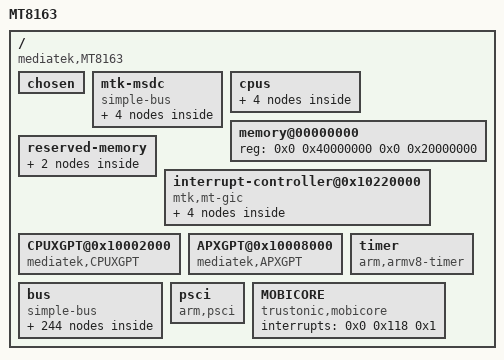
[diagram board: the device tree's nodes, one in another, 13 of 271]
/dts-v1/;

/ {
	model = "MT8163";
	compatible = "mediatek,MT8163";
	interrupt-parent = <0x1>;
	#address-cells = <0x2>;
	#size-cells = <0x2>;

	chosen {
		bootargs = "console=tty0 console=ttyMT0,921600n1 root=/dev/ram initrd=0x44000200,0x200000 loglevel=8";
	};

	mtk-msdc {
		compatible = "simple-bus";
		#address-cells = <0x1>;
		#size-cells = <0x1>;
		ranges = <0x0 0x0 0x0 0xffffffff>;

		MSDC0@0x11230000 {
			compatible = "mediatek,MSDC0";
			reg = <0x11230000 0x10000 0x10001e84 0x8 0x102061c0 0x4 0x10005000 0x1000 0x10000000 0x230>;
			interrupts = <0x0 0x4f 0x8>;
			status = "okay";
		};

		MSDC1@0x11240000 {
			compatible = "mediatek,MSDC1";
			reg = <0x11240000 0x10000 0x10001e84 0x8 0x10005000 0x1000 0x10000000 0x230>;
			interrupts = <0x0 0x50 0x8>;
			status = "okay";
		};

		MSDC2@0x11250000 {
			compatible = "mediatek,MSDC2";
			reg = <0x11250000 0x10000 0x10001e84 0x8 0x10005000 0x1000 0x10000000 0x230>;
			interrupts = <0x0 0x51 0x8>;
			status = "disabled";
		};

		MSDC3@0x11260000 {
			compatible = "mediatek,MSDC3";
			reg = <0x11260000 0x10000 0x10001e84 0x8 0x102061c0 0x4 0x10005000 0x1000 0x10000000 0x230>;
			interrupts = <0x0 0x52 0x8>;
			status = "disabled";
		};
	};

	cpus {
		#address-cells = <0x1>;
		#size-cells = <0x0>;

		cpu@0 {
			device_type = "cpu";
			compatible = "arm,cortex-a53";
			reg = <0x0>;
			enable-method = "mt-boot";
			cpu-release-addr = <0x0 0x40000200>;
			clock-frequency = "M|m";
			linux,phandle = <0x2>;
			phandle = <0x2>;
		};

		cpu@1 {
			device_type = "cpu";
			compatible = "arm,cortex-a53";
			reg = <0x1>;
			enable-method = "mt-boot";
			cpu-release-addr = <0x0 0x40000200>;
			clock-frequency = "M|m";
			linux,phandle = <0x3>;
			phandle = <0x3>;
		};

		cpu@2 {
			device_type = "cpu";
			compatible = "arm,cortex-a53";
			reg = <0x2>;
			enable-method = "mt-boot";
			cpu-release-addr = <0x0 0x40000200>;
			clock-frequency = "M|m";
			linux,phandle = <0x4>;
			phandle = <0x4>;
		};

		cpu@3 {
			device_type = "cpu";
			compatible = "arm,cortex-a53";
			reg = <0x3>;
			enable-method = "mt-boot";
			cpu-release-addr = <0x0 0x40000200>;
			clock-frequency = "M|m";
			linux,phandle = <0x5>;
			phandle = <0x5>;
		};
	};

	memory@00000000 {
		device_type = "memory";
		reg = <0x0 0x40000000 0x0 0x20000000>;
	};

	reserved-memory {
		#address-cells = <0x2>;
		#size-cells = <0x2>;
		ranges;

		consys-reserve-memory {
			compatible = "consys-reserve-memory";
			no-map;
			size = <0x0 0x200000>;
			alignment = <0x0 0x200000>;
		};

		ATF-reserved-memory {
			compatible = "ATF-reserved-memory";
			no-map;
			reg = <0x0 0x43000000 0x0 0x30000>;
		};
	};

	interrupt-controller@0x10220000 {
		compatible = "mtk,mt-gic";
		#interrupt-cells = <0x3>;
		#address-cells = <0x0>;
		interrupt-controller;
		reg = <0x0 0x10221000 0x0 0x1000 0x0 0x10222000 0x0 0x1000 0x0 0x10200620 0x0 0x1000>;
		interrupts = <0x1 0x9 0xf04>;
		linux,phandle = <0x1>;
		phandle = <0x1>;

		gic-cpuif@0 {
			compatible = "arm,gic-cpuif";
			cpuif-id = <0x0>;
			cpu = <0x2>;
		};

		gic-cpuif@1 {
			compatible = "arm,gic-cpuif";
			cpuif-id = <0x1>;
			cpu = <0x3>;
		};

		gic-cpuif@2 {
			compatible = "arm,gic-cpuif";
			cpuif-id = <0x2>;
			cpu = <0x4>;
		};

		gic-cpuif@3 {
			compatible = "arm,gic-cpuif";
			cpuif-id = <0x3>;
			cpu = <0x5>;
		};
	};

	CPUXGPT@0x10002000 {
		compatible = "mediatek,CPUXGPT";
		reg = <0x0 0x10200000 0x0 0x1000>;
		interrupts = <0x0 0x40 0x4 0x0 0x41 0x4 0x0 0x42 0x4 0x0 0x43 0x4 0x0 0x44 0x4 0x0 0x45 0x4 0x0 0x46 0x4 0x0 0x47 0x4>;
	};

	APXGPT@0x10008000 {
		compatible = "mediatek,APXGPT";
		reg = <0x0 0x10008000 0x0 0x1000>;
		interrupts = <0x0 0x98 0x8>;
		clock-frequency = <0xc65d40>;
	};

	timer {
		compatible = "arm,armv8-timer";
		interrupts = <0x1 0xd 0x8 0x1 0xe 0x8 0x1 0xb 0x8 0x1 0xa 0x8>;
		clock-frequency = <0xc65d40>;
	};

	bus {
		compatible = "simple-bus";
		#address-cells = <0x1>;
		#size-cells = <0x1>;
		ranges = <0x0 0x0 0x0 0xffffffff>;

		TOPCKGEN@0x10000000 {
			compatible = "mediatek,TOPCKGEN";
			reg = <0x10000000 0x1000>;
		};

		INFRACFG_AO@0x10001000 {
			compatible = "mediatek,INFRACFG_AO";
			reg = <0x10001000 0x1000>;
		};

		IOCFG_L@0x10002000 {
			compatible = "mediatek,IOCFG_L";
			reg = <0x10002000 0x400>;
		};

		IOCFG_B@0x10002400 {
			compatible = "mediatek,IOCFG_B";
			reg = <0x10002400 0x400>;
		};

		IOCFG_R@0x10002800 {
			compatible = "mediatek,IOCFG_R";
			reg = <0x10002800 0x400>;
		};

		IOCFG_T@0x10002C00 {
			compatible = "mediatek,IOCFG_T";
			reg = <0x10002c00 0x400>;
		};

		PERICFG@0x10003000 {
			compatible = "mediatek,PERICFG";
			reg = <0x10003000 0x1000>;
		};

		DRAMC0@0x10004000 {
			compatible = "mediatek,DRAMC0";
			reg = <0x10004000 0x1000>;
		};

		GPIO@0x10005000 {
			compatible = "mediatek,GPIO";
			reg = <0x10005000 0x1000>;
		};

		SLEEP@0x10006000 {
			compatible = "mediatek,SLEEP";
			reg = <0x10006000 0x1000>;
			interrupts = <0x0 0xa3 0x8 0x0 0xa4 0x8 0x0 0xa5 0x8 0x0 0xa6 0x8 0x0 0xa7 0x8 0x0 0xa8 0x8 0x0 0xa9 0x8 0x0 0xaa 0x8>;
		};

		TOPRGU@0x10007000 {
			compatible = "mediatek,TOPRGU";
			reg = <0x10007000 0x1000>;
			interrupts = <0x0 0x80 0x2>;
		};

		RSVD@0x10009000 {
			compatible = "mediatek,RSVD";
			reg = <0x10009000 0x1000>;
		};

		SEJ@0x1000A000 {
			compatible = "mediatek,SEJ";
			reg = <0x1000a000 0x1000>;
			interrupts = <0x0 0xac 0x8>;
		};

		EINTC@0x1000B000 {
			compatible = "mtk,mt-eic";
			reg = <0x1000b000 0x1000>;
			interrupts = <0x0 0x99 0x4>;
			#interrupt-cells = <0x2>;
			interrupt-controller;
			max_eint_num = <0xa9>;
			mapping_table_entry = <0x9b>;
			max_deint_cnt = <0x4>;
			deint_possible_irq = <0xbd 0xbe 0xbf 0xc0>;
			mapping_table = <0x0 0x16 0x1 0x17 0x2 0x18 0x3 0x19 0x4 0x1a 0x5 0x1b 0x6 0x1c 0x7 0x1d 0x8 0x1e 0x9 0x1f 0xa 0x20 0xb 0x21 0xc 0x22 0xd 0x23 0xe 0x24 0xf 0x25 0x10 0x26 0x11 0x27 0x12 0x28 0x13 0x29 0x14 0x2a 0x15 0x2b 0x16 0x0 0x17 0x1 0x18 0x2 0x19 0x3 0x1a 0x4 0x1b 0x5 0x1c 0x6 0x1d 0x7 0x1e 0x8 0x1f 0x9 0x20 0xa 0x21 0x2c 0x22 0x2d 0x23 0x2e 0x24 0x2f 0x25 0x30 0x26 0x31 0x27 0x32 0x28 0x33 0x29 0x34 0x2a 0x35 0x2b 0xb 0x2c 0xc 0x2d 0xd 0x2e 0xe 0x2f 0xf 0x30 0x10 0x31 0x11 0x32 0x12 0x33 0x13 0x34 0x14 0x35 0x36 0x36 0x37 0x37 0x38 0x38 0x39 0x39 0x3a 0x3a 0x3b 0x3b 0x3c 0x3c 0x3d 0x3d 0x3e 0x3e 0x3f 0x3f 0x40 0x40 0x41 0x41 0x42 0x42 0x43 0x43 0x44 0x44 0x45 0x45 0x46 0x46 0x47 0x47 0x48 0x48 0x49 0x49 0x4a 0x4a 0x4b 0x4b 0x4c 0x4c 0x4d 0x4d 0x4e 0x4e 0x4f 0x4f 0x50 0x50 0x51 0x51 0x52 0x52 0x53 0x53 0x54 0x54 0x55 0x55 0x56 0x56 0x57 0x57 0x58 0x58 0x59 0x59 0x5a 0x5a 0x5b 0x5b 0x5c 0x5c 0x5d 0x5d 0x5e 0x5e 0x5f 0x5f 0x60 0x60 0x61 0x61 0x62 0x62 0x63 0x63 0x64 0x64 0x65 0x65 0x66 0x66 0x67 0x67 0x68 0x68 0x69 0x69 0x6a 0x6a 0x6b 0x6b 0x6c 0x6c 0x6d 0x6d 0x6e 0x6e 0x6f 0x6f 0x70 0x70 0x71 0x71 0x72 0x72 0x73 0x73 0x74 0x74 0x75 0x75 0x76 0x76 0x77 0x77 0x78 0x78 0x79 0x79 0x7a 0x7a 0x7b 0x7b 0x7c 0x7c 0x7d 0x7d 0x7e 0x7e 0x7f 0x7f 0x80 0x80 0x81 0x81 0x82 0x82 0x83 0x83 0x84 0x84 0x85 0x85 0x86 0x86 0x87 0x87 0x88 0x88 0x89 0x89 0x8a 0x8a 0x8b 0x8b 0x8c 0x8c 0x8d 0x8d 0x8e 0x8e 0x15 0x8f 0x8f 0x90 0x90 0x91 0x91 0x92 0x92 0x93 0x93 0x94 0x94 0x95 0x95 0x96 0x96 0x97 0x97 0x98 0x98 0x99 0x99 0x9a 0x9a>;
			linux,phandle = <0x6>;
			phandle = <0x6>;

			CHR_STAT@1 {
				compatible = "mediatek, CHR_STAT-eint";
				interrupt-parent = <0x6>;
				interrupts = <0x1 0x8>;
				debounce = <0x1 0x0>;
			};

			ACCDET@4 {
				compatible = "mediatek, ACCDET-eint";
				interrupt-parent = <0x6>;
				interrupts = <0x4 0x8>;
				debounce = <0x4 0x3e800>;
			};

			MSDC1_INS@6 {
				compatible = "mediatek, MSDC1_INS-eint";
				interrupt-parent = <0x6>;
				interrupts = <0x6 0x8>;
				debounce = <0x6 0x3e8>;
			};

			ALS@8 {
				compatible = "mediatek, ALS-eint";
				interrupt-parent = <0x6>;
				interrupts = <0x8 0x8>;
				debounce = <0x8 0x0>;
			};

			GYRO@18 {
				compatible = "mediatek, GYRO-eint";
				interrupt-parent = <0x6>;
				interrupts = <0x12 0x4>;
				debounce = <0x12 0x0>;
			};

			GSE_1@19 {
				compatible = "mediatek, GSE_1-eint";
				interrupt-parent = <0x6>;
				interrupts = <0x13 0x4>;
				debounce = <0x13 0x0>;
			};

			MSE@20 {
				compatible = "mediatek, MSE-eint";
				interrupt-parent = <0x6>;
				interrupts = <0x14 0x8>;
				debounce = <0x14 0x0>;
			};

			TOUCH_PANEL@46 {
				compatible = "mediatek, TOUCH_PANEL-eint";
				interrupt-parent = <0x6>;
				interrupts = <0x2e 0x2>;
				debounce = <0x2e 0x0>;
			};
		};

		EMIMPU@0x10203000 {
			compatible = "mediatek,EMIMPU";
			reg = <0x10203000 0x1000>;
			interrupts = <0x0 0x85 0x8>;
		};

		APMIXED@0x1000C000 {
			compatible = "mediatek,APMIXED";
			reg = <0x1000c000 0x1000>;
			interrupts = <0x0 0x88 0x1>;
		};

		FHCTL@0x1000CF00 {
			compatible = "mediatek,FHCTL";
			reg = <0x1000cf00 0x100>;
		};

		PWRAP@0x1000D000 {
			compatible = "mediatek,PWRAP";
			reg = <0x1000d000 0x1000>;
			interrupts = <0x0 0xa1 0x4>;
		};

		DEVAPC_AO@0x1000E000 {
			compatible = "mediatek,DEVAPC_AO";
			reg = <0x1000e000 0x1000>;
		};

		DDRPHY@0x1000F000 {
			compatible = "mediatek,DDRPHY";
			reg = <0x1000f000 0x1000>;
		};

		KP@0x10010000 {
			compatible = "mediatek,KP";
			reg = <0x10010000 0x1000>;
			interrupts = <0x0 0xa2 0x2>;
		};

		TOPMISC@0x10011000 {
			compatible = "mediatek,TOPMISC";
			reg = <0x10011000 0x1000>;
		};

		SCP_SRAM@0x10020000 {
			compatible = "mediatek,SCP_SRAM";
			reg = <0x10020000 0x38000>;
		};

		SCP_CFGREG@0x10058000 {
			compatible = "mediatek,SCP_CFGREG";
			reg = <0x10058000 0x400>;
			interrupts = <0x0 0xae 0x4>;
		};

		SCP_MAD@0x10058400 {
			compatible = "mediatek,SCP_MAD";
			reg = <0x10058400 0x400>;
		};

		SCP_INTC@0x10058800 {
			compatible = "mediatek,SCP_INTC";
			reg = <0x10058800 0x400>;
		};

		SCP_TIMER@0x10058C00 {
			compatible = "mediatek,SCP_TIMER";
			reg = <0x10058c00 0x400>;
		};

		SCP_CLK_CTRL@0x10059000 {
			compatible = "mediatek,SCP_CLK_CTRL";
			reg = <0x10059000 0x400>;
		};

		SCP_I2C0@0x10059400 {
			compatible = "mediatek,SCP_I2C0";
			cell-index = <0x3>;
			reg = <0x10059400 0x400>;
		};

		SCP_I2C1@0x10059800 {
			compatible = "mediatek,SCP_I2C1";
			cell-index = <0x4>;
			reg = <0x10059800 0x400>;
		};

		SCP_I2C2@0x10059C00 {
			compatible = "mediatek,SCP_I2C2";
			cell-index = <0x5>;
			reg = <0x10059c00 0x400>;
		};

		SCP_GPIO@0x1005A000 {
			compatible = "mediatek,SCP_GPIO";
			reg = <0x1005a000 0x400>;
		};

		SCP_UART@0x1005A400 {
			compatible = "mediatek,SCP_UART";
			reg = <0x1005a400 0x400>;
		};

		SCP_CIRQ_EINT@0x1005A800 {
			compatible = "mediatek,SCP_CIRQ_EINT";
			reg = <0x1005a800 0x400>;
		};

		SCP_PMICWP2P@0x1005E000 {
			compatible = "mediatek,SCP_PMICWP2P";
			reg = <0x1005e000 0x1000>;
		};

		SCP_PMICWP2P@0x1005F000 {
			compatible = "mediatek,SCP_PMICWP2P";
			reg = <0x1005f000 0x1000>;
		};

		DBG_ETB@0x10100000 {
			compatible = "mediatek,DBG_ETB";
			reg = <0x10410000 0x10000 0x10430000 0x10000 0x10440000 0x10000 0x104a0000 0x10000>;
		};

		DBG_DEBUG {
			compatible = "mediatek,DBG_DEBUG";
			num = <0x8>;
			reg = <0x10810000 0x1000 0x10910000 0x1000 0x10a10000 0x1000 0x10b10000 0x1000 0x10c10000 0x1000 0x10d10000 0x1000 0x10e10000 0x1000 0x10f10000 0x1000>;
		};

		DBG_ETM {
			compatible = "mediatek,DBG_ETM";
			num = <0x8>;
			reg = <0x10840000 0x1000 0x10940000 0x1000 0x10a40000 0x1000 0x10b40000 0x1000 0x10c40000 0x1000 0x10d40000 0x1000 0x10e40000 0x1000 0x10f40000 0x1000>;
		};

		BAT_METTER {
			compatible = "mediatek,bat_meter";
		};

		BAT_NOTIFY {
			compatible = "mediatek,bat_notify";
		};

		MCUCFG@0x10200000 {
			compatible = "mediatek,MCUCFG";
			reg = <0x10200000 0x1000>;
		};

		INFRACFG@0x10201000 {
			compatible = "mediatek,INFRACFG";
			reg = <0x10201000 0x1000>;
		};

		SRAMROM@0x10202000 {
			compatible = "mediatek,SRAMROM";
			reg = <0x10202000 0x1000>;
		};

		EMI@0x10203000 {
			compatible = "mediatek,EMI";
			reg = <0x10203000 0x1000>;
			interrupts = <0x0 0x87 0x8>;
		};

		SYS_CIRQ@0x10204000 {
			compatible = "mediatek,SYS_CIRQ";
			reg = <0x10204000 0x1000>;
		};

		M4U@0x10205000 {
			cell-index = <0x0>;
			compatible = "mediatek,M4U";
			reg = <0x10205000 0x1000>;
			interrupts = <0x0 0x93 0x8>;
		};

		EFUSEC@0x10206000 {
			compatible = "mediatek,EFUSEC";
			reg = <0x10206000 0x1000>;
			interrupts = <0x0 0x89 0x1>;
		};

		DEVAPC@0x10207000 {
			compatible = "mediatek,DEVAPC";
			reg = <0x10207000 0x1000>;
			interrupts = <0x0 0x86 0x8>;
		};

		BUS_DBG@0x10208000 {
			compatible = "mediatek,BUS_DBG";
			reg = <0x10208000 0x1000>;
			interrupts = <0x0 0x84 0x8>;
		};

		AP_CCIF0@0x10209000 {
			compatible = "mediatek,AP_CCIF0";
			reg = <0x10209000 0x1000>;
		};

		MD_CCIF0@0x1020A000 {
			compatible = "mediatek,MD_CCIF0";
			reg = <0x1020a000 0x1000>;
		};

		AP_CCIF1@0x1020B000 {
			compatible = "mediatek,AP_CCIF1";
			reg = <0x1020b000 0x1000>;
			interrupts = <0x0 0x8d 0x8 0x0 0xaf 0x2>;
			cell-index = <0x1>;
			ccif,major = <0xa9>;
			ccif,minor_base = <0x0>;
			ccif,capability = <0x0>;
		};

		MD_CCIF1@0x1020C000 {
			compatible = "mediatek,MD_CCIF1";
			reg = <0x1020c000 0x1000>;
		};

		INFRA_MBIST@0x1020D000 {
			compatible = "mediatek,INFRA_MBIST";
			reg = <0x1020d000 0x1000>;
		};

		DRAMC_NAO@0x1020E000 {
			compatible = "mediatek,DRAMC_NAO";
			reg = <0x1020e000 0x1000>;
		};

		TRNG@0x1020F000 {
			compatible = "mediatek,TRNG";
			reg = <0x1020f000 0x1000>;
			interrupts = <0x0 0x8c 0x8>;
		};

		GCPU@0x10210000 {
			compatible = "mediatek,GCPU";
			reg = <0x10210000 0x1000>;
			interrupts = <0x0 0x97 0x8>;
		};

		MD2MD_MD1_CCIF0@0x10211000 {
			compatible = "mediatek,MD2MD_MD1_CCIF0";
			reg = <0x10211000 0x1000>;
		};

		GCE@0x10212000 {
			compatible = "mediatek,GCE";
			reg = <0x10212000 0x1000>;
			interrupts = <0x0 0x8f 0x8 0x0 0x90 0x8>;
		};

		MD2MD_MD2_CCIF0@0x10213000 {
			compatible = "mediatek,MD2MD_MD2_CCIF0";
			reg = <0x10213000 0x1000>;
		};

		PERISYS_IOMMU@0x10214000 {
			cell-index = <0x1>;
			compatible = "mediatek,PERISYS_IOMMU";
			reg = <0x10214000 0x1000>;
			interrupts = <0x0 0x91 0x8>;
		};

		MIPI_TX0@0x10215000 {
			compatible = "mediatek,MIPI_TX0";
			reg = <0x10215000 0x1000>;
		};

		MIPI_RX_ANA_CSI0@0x10217000 {
			compatible = "mediatek,MIPI_RX_ANA_CSI0";
			reg = <0x10217000 0x1000>;
		};

		MIPI_RX_ANA_CSI1@0x10218000 {
			compatible = "mediatek,MIPI_RX_ANA_CSI1";
			reg = <0x10218000 0x1000>;
		};

		GIC@0x10220000 {
			compatible = "mediatek,GIC";
			reg = <0x10220000 0x8000>;
		};

		CCI400@0x10390000 {
			compatible = "mediatek,CCI400";
			reg = <0x10390000 0x10000>;
		};

		DBGAPB@0x10400000 {
			compatible = "mediatek,DBGAPB";
			reg = <0x10400000 0xc00000>;
			interrupts = <0x0 0x83 0x8>;
		};

		AP_DMA@0x11000000 {
			compatible = "mediatek,AP_DMA";
			reg = <0x11000000 0x1000>;
			interrupts = <0x0 0x6f 0x8>;
		};

		AUXADC@0x11001000 {
			compatible = "mediatek,AUXADC";
			reg = <0x11001000 0x1000>;
			interrupts = <0x0 0x4c 0x2>;
		};

		AP_DMA_UART0_TX@0x11000300 {
			compatible = "mediatek,AP_DMA_UART0_TX";
			reg = <0x11000300 0x80>;
			interrupts = <0x0 0x66 0x8>;
		};

		AP_DMA_UART0_RX@0x11000380 {
			compatible = "mediatek,AP_DMA_UART0_RX";
			reg = <0x11000380 0x80>;
			interrupts = <0x0 0x67 0x8>;
		};

		AP_DMA_UART1_TX@0x11000400 {
			compatible = "mediatek,AP_DMA_UART1_TX";
			reg = <0x11000400 0x80>;
			interrupts = <0x0 0x68 0x8>;
		};

		AP_DMA_UART1_RX@0x11000480 {
			compatible = "mediatek,AP_DMA_UART1_RX";
			reg = <0x11000480 0x80>;
			interrupts = <0x0 0x69 0x8>;
		};

		AP_DMA_UART2_TX@0x11000500 {
			compatible = "mediatek,AP_DMA_UART2_TX";
			reg = <0x11000500 0x80>;
			interrupts = <0x0 0x6a 0x8>;
		};

		AP_DMA_UART2_RX@0x11000580 {
			compatible = "mediatek,AP_DMA_UART2_RX";
			reg = <0x11000580 0x80>;
			interrupts = <0x0 0x6b 0x8>;
		};

		AP_DMA_UART3_TX@0x11000600 {
			compatible = "mediatek,AP_DMA_UART3_TX";
			reg = <0x11000600 0x80>;
			interrupts = <0x0 0x6c 0x8>;
		};

		AP_DMA_UART3_RX@0x11000680 {
			compatible = "mediatek,AP_DMA_UART3_RX";
			reg = <0x11000680 0x80>;
			interrupts = <0x0 0x6d 0x8>;
		};

		AP_UART0@0x11002000 {
			cell-index = <0x0>;
			compatible = "mediatek,AP_UART0";
			reg = <0x11002000 0x1000>;
			interrupts = <0x0 0x5b 0x8>;
		};

		AP_UART1@0x11003000 {
			cell-index = <0x1>;
			compatible = "mediatek,AP_UART1";
			reg = <0x11003000 0x1000>;
			interrupts = <0x0 0x5c 0x8>;
		};

		AP_UART2@0x11004000 {
			cell-index = <0x2>;
			compatible = "mediatek,AP_UART2";
			reg = <0x11004000 0x1000>;
			interrupts = <0x0 0x5d 0x8>;
		};

		AP_UART3@0x11005000 {
			cell-index = <0x3>;
			compatible = "mediatek,AP_UART3";
			reg = <0x11005000 0x1000>;
			interrupts = <0x0 0x5e 0x8>;
		};

		PWM@0x11006000 {
			compatible = "mediatek,PWM";
			reg = <0x11006000 0x1000>;
			interrupts = <0x0 0x4d 0x8>;
		};

		I2C0@0x11007000 {
			compatible = "mediatek,I2C0";
			cell-index = <0x0>;
			reg = <0x11007000 0x1000>;
			#address-cells = <0x1>;
			#size-cells = <0x0>;
			interrupts = <0x0 0x54 0x8>;

			gt9xx@5d {
				compatible = "gt9xx";
				reg = <0x5d>;
			};

			mt6306@64 {
				compatible = "mediatek,mt6306";
				reg = <0x64>;
			};
		};

		I2C1@0x11008000 {
			compatible = "mediatek,I2C1";
			cell-index = <0x1>;
			reg = <0x11008000 0x1000>;
			#address-cells = <0x1>;
			#size-cells = <0x0>;
			interrupts = <0x0 0x55 0x8>;

			yas533@2e {
				compatible = "yas533";
				reg = <0x2e>;
			};

			mpu-6515@68 {
				compatible = "mpu-6515";
				reg = <0x68>;
			};

			bmp180@77 {
				compatible = "bmp180";
				reg = <0x77>;
			};

			cm36652@60 {
				compatble = "cm36652";
				reg = <0x60>;
			};

			mt6605@28 {
				compatible = "mediatek,mt6605";
				reg = <0x28>;
			};
		};

		I2C2@0x11009000 {
			compatible = "mediatek,I2C2";
			cell-index = <0x2>;
			reg = <0x11009000 0x1000>;
			#address-cells = <0x1>;
			#size-cells = <0x0>;
			interrupts = <0x0 0x56 0x8>;

			bq24296@6b {
				compatible = "ti,bq24296";
				reg = <0x6b>;
			};
		};

		SPI1@0x1100A000 {
			compatible = "mediatek,SPI1";
			cell-index = <0x0>;
			spi-padmacro = <0x0>;
			reg = <0x1100a000 0x1000>;
			interrupts = <0x0 0x76 0x8>;
		};

		THERM_CTRL@0x1100B000 {
			compatible = "mediatek,THERM_CTRL";
			reg = <0x1100b000 0x1000>;
			interrupts = <0x0 0x4e 0x8>;
		};

		PTP_FSM@0x1100B000 {
			compatible = "mediatek,PTP_FSM";
			reg = <0x1100b000 0x1000>;
			interrupts = <0x0 0x7d 0x8>;
		};

		AP_DMA_BTIF_TX@0x11000700 {
			compatible = "mediatek,AP_DMA_BTIF_TX";
			reg = <0x11000700 0x80>;
			interrupts = <0x0 0x6e 0x8>;
		};

		AP_DMA_BTIF_RX@0x11000780 {
			compatible = "mediatek,AP_DMA_BTIF_RX";
			reg = <0x11000780 0x80>;
			interrupts = <0x0 0x6f 0x8>;
		};

		BTIF@0x1100C000 {
			compatible = "mediatek,BTIF";
			reg = <0x1100c000 0x1000>;
			interrupts = <0x0 0x70 0x8>;
		};

		mt3326-gps@0xffffffff {
			compatible = "mediatek,mt3326-gps";
		};

		BTCVSD@0x18000000 {
			compatible = "mediatek,audio_bt_cvsd";
			reg = <0x18000000 0x10000 0x18080000 0x10000>;
			interrupts = <0x0 0x10c 0x8>;
		};

		CONSYS@0x18070000 {
			compatible = "mediatek,CONSYS";
			reg = <0x18070000 0x200 0x10007000 0x100 0x10000000 0x2000 0x10006000 0x1000>;
			interrupts = <0x0 0xed 0x8>;
		};

		WIFI@0x180F0000 {
			compatible = "mediatek,WIFI";
			reg = <0x180f0000 0x5c>;
			interrupts = <0x0 0xee 0x8>;
		};

		NFI@0x1100D000 {
			compatible = "mediatek,NFI";
			reg = <0x1100d000 0x1000>;
			interrupts = <0x0 0x60 0x8>;
			nfi_bus_width = <0x8>;
			nfi_access_timing = <0x4333>;
			nfi_cs_num = <0x2>;
			nand_sec_size = <0x200>;
			nand_sec_shift = <0x9>;
			nand_ecc_size = <0x800>;
			nand_ecc_bytes = <0x20>;
			nand_ecc_mode = <0x2>;
		};

		NFIECC@0x1100E000 {
			compatible = "mediatek,NFIECC";
			reg = <0x1100e000 0x1000>;
			interrupts = <0x0 0x5f 0x8>;
		};

		DUMCHAR {
			compatible = "mediatek,dummy_char";
		};

		USB0@0x11200000 {
			compatible = "mediatek,USB0";
			cell-index = <0x0>;
			reg = <0x11200000 0x10000 0x11210000 0x10000>;
			interrupts = <0x0 0x48 0x8>;
			mode = <0x2>;
			multipoint = <0x1>;
			dyn_fifo = <0x1>;
			soft_con = <0x1>;
			dma = <0x1>;
			num_eps = <0x10>;
			dma_channels = <0x8>;
			iddig_gpio = <0x26 0x0>;
			drvvbus_gpio = <0x23 0x0>;
		};

		BATTERY {
			compatible = "mediatek,battery";
		};

		AUDIO@0x11220000 {
			compatible = "mediatek,AUDIO";
			reg = <0x11220000 0x10000>;
			interrupts = <0x0 0x8e 0x8>;
		};

		MT_SOC_DL1_PCM@0x11220000 {
			compatible = "mediatek,mt_soc_pcm_dl1";
			reg = <0x11220000 0x1000>;
			interrupts = <0x0 0x8e 0x8>;
			audclk-gpio = <0x7 0x0>;
			audmiso-gpio = <0x8 0x0>;
			audmosi-gpio = <0x9 0x0>;
			vowclk-gpio = <0x94 0x0>;
			extspkamp-gpio = <0x18 0x0>;
			i2s1clk-gpio = <0x87 0x0>;
			i2s1dat-gpio = <0x89 0x0>;
			i2s1mclk-gpio = <0x86 0x0>;
			i2s1ws-gpio = <0x88 0x0>;
		};

		MT_SOC_UL1_PCM@0x11220000 {
			compatible = "mediatek,mt_soc_pcm_capture";
		};

		MT_SOC_VOICE_MD1@0x11220000 {
			compatible = "mediatek,mt_soc_pcm_voice_md1";
		};

		MT_SOC_HDMI_PCM@0x11220000 {
			compatible = "mediatek,mt_soc_pcm_hdmi";
		};

		MT_SOC_ULDLLOOPBACK_PCM@0x11220000 {
			compatible = "mediatek,mt_soc_pcm_uldlloopback";
		};

		MT_SOC_I2S0_PCM@0x11220000 {
			compatible = "mediatek,mt_soc_pcm_dl1_i2s0";
		};

		MT_SOC_MRGRX_PCM@0x11220000 {
			compatible = "mediatek,mt_soc_pcm_mrgrx";
		};

		MT_SOC_MRGRX_AWB_PCM@0x11220000 {
			compatible = "mediatek,mt_soc_pcm_mrgrx_awb";
		};

		MT_SOC_FM_I2S_PCM@0x11220000 {
			compatible = "mediatek,mt_soc_pcm_fm_i2s";
		};

		MT_SOC_FM_I2S_AWB_PCM@0x11220000 {
			compatible = "mediatek,mt_soc_pcm_fm_i2s_awb";
		};

		MT_SOC_I2S0DL1_PCM@0x11220000 {
			compatible = "mediatek,mt_soc_pcm_dl1_i2s0Dl1";
		};

		MT_SOC_DL1_AWB_PCM@0x11220000 {
			compatible = "mediatek,mt_soc_pcm_dl1_awb";
		};

		MT_SOC_VOICE_MD1_BT@0x11220000 {
			compatible = "mediatek,mt_soc_pcm_voice_md1_bt";
		};

		MT_SOC_VOIP_BT_OUT@0x11220000 {
			compatible = "mediatek,mt_soc_pcm_dl1_bt";
		};

		MT_SOC_VOIP_BT_IN@0x11220000 {
			compatible = "mediatek,mt_soc_pcm_bt_dai";
		};

		MT_SOC_TDMRX_PCM@0x11220000 {
			compatible = "mediatek,mt_soc_tdm_capture";
		};

		MT_SOC_FM_MRGTX_PCM@0x11220000 {
			compatible = "mediatek,mt_soc_pcm_fmtx";
		};

		MT_SOC_UL2_PCM@0x11220000 {
			compatible = "mediatek,mt_soc_pcm_capture2";
		};

		MT_SOC_I2S0_AWB_PCM@0x11220000 {
			compatible = "mediatek,mt_soc_pcm_i2s0_awb";
		};

		MT_SOC_VOICE_MD2@0x11220000 {
			compatible = "mediatek,mt_soc_pcm_voice_md2";
		};

		MT_SOC_ROUTING_PCM@0x11220000 {
			compatible = "mediatek,mt_soc_pcm_routing";
		};

		MT_SOC_VOICE_MD2_BT@0x11220000 {
			compatible = "mediatek,mt_soc_pcm_voice_md2_bt";
		};

		MT_SOC_HP_IMPEDANCE_PCM@0x11220000 {
			compatible = "mediatek,Mt_soc_pcm_hp_impedance";
		};

		MT_SOC_CODEC_NAME@0x11220000 {
			compatible = "mediatek,mt_soc_codec_63xx";
		};

		MT_SOC_DUMMY_PCM@0x11220000 {
			compatible = "mediatek,mt_soc_pcm_dummy";
		};

		MT_SOC_CODEC_DUMMY_NAME@0x11220000 {
			compatible = "mediatek,mt_soc_codec_dummy";
		};

		MT_SOC_ROUTING_DAI_NAME@0x11220000 {
			compatible = "mediatek,mt_soc_dai_routing";
		};

		MT_SOC_DAI_NAME@0x11220000 {
			compatible = "mediatek,mt_soc_dai_stub";
		};

		ICUSB@0x11270000 {
			compatible = "mediatek,ICUSB";
			reg = <0x11270000 0x10000 0x11210000 0x10000>;
			interrupts = <0x0 0x49 0x8>;
		};

		G3D_CONFIG@0x13000000 {
			compatible = "mediatek,G3D_CONFIG", "mediatek,g3d_sapphire_lite";
			reg = <0x13000000 0x5000>;
			interrupts = <0x0 0xe1 0x8>;
		};

		MALI@0x13040000 {
			compatible = "arm,malit720", "arm,mali-t72x", "arm,malit7xx", "arm,mali-midgard";
			reg = <0x13040000 0x4000>;
			interrupts = <0x0 0xe3 0x8 0x0 0xe2 0x8 0x0 0xe1 0x8>;
			interrupt-names = "JOB", "MMU", "GPU";
			clock-frequency = <0x1efe9200>;
		};

		G3D_IOMMU@0x13005000 {
			cell-index = <0x2>;
			compatible = "mediatek,G3D_IOMMU";
			reg = <0x13005000 0x1000>;
			interrupts = <0x0 0xe2 0x8>;
		};

		MMSYS_CONFIG@0x14000000 {
			compatible = "mediatek,MMSYS_CONFIG";
			reg = <0x14000000 0x1000>;
		};

		MDP_RDMA@0x14001000 {
			compatible = "mediatek,MDP_RDMA";
			reg = <0x14001000 0x1000>;
			interrupts = <0x0 0xb2 0x8>;
		};

		MDP_RSZ0@0x14002000 {
			compatible = "mediatek,MDP_RSZ0";
			reg = <0x14002000 0x1000>;
			interrupts = <0x0 0xb3 0x8>;
		};

		MDP_RSZ1@0x14003000 {
			compatible = "mediatek,MDP_RSZ1";
			reg = <0x14003000 0x1000>;
			interrupts = <0x0 0xb4 0x8>;
		};

		MDP_WDMA@0x14004000 {
			compatible = "mediatek,MDP_WDMA";
			reg = <0x14004000 0x1000>;
			interrupts = <0x0 0xb6 0x8>;
		};

		MDP_WROT@0x14005000 {
			compatible = "mediatek,MDP_WROT";
			reg = <0x14005000 0x1000>;
			interrupts = <0x0 0xb7 0x8>;
		};

		MDP_TDSHP@0x14006000 {
			compatible = "mediatek,MDP_TDSHP";
			reg = <0x14006000 0x1000>;
			interrupts = <0x0 0xb5 0x8>;
		};

		DISPSYS@0x10002000 {
			compatible = "mediatek,DISPSYS";
			reg = <0x14007000 0x1000 0x14008000 0x1000 0x14009000 0x1000 0x1400a000 0x1000 0x1400b000 0x1000 0x1400c000 0x1000 0x1400d000 0x1000 0x1400e000 0x1000 0x1400f000 0x1000 0x14010000 0x1000 0x14011000 0x1000 0x14014000 0x1000 0x14018000 0x1000 0x14015000 0x1000 0x14012000 0x1000 0x14013000 0x1000 0x1401c000 0x1000 0x14000000 0x1000 0x14016000 0x1000 0x14017000 0x1000 0x10215000 0x1000 0x10215800 0x1000 0x1401b200 0x1000 0x10206000 0x1000 0x10000000 0x1000 0x10005000 0x1000 0x100000a0 0x1000 0x1000c270 0x1000 0x1000c274 0x1000>;
			interrupts = <0x0 0xb8 0x8 0x0 0xb9 0x8 0x0 0xba 0x8 0x0 0xbb 0x8 0x0 0xbc 0x8 0x0 0xbd 0x8 0x0 0xbe 0x8 0x0 0xbf 0x8 0x0 0xc0 0x8 0x0 0xc1 0x8 0x0 0xc2 0x8 0x0 0x0 0x8 0x0 0xc6 0x8 0x0 0xb1 0x8 0x0 0xc3 0x8 0x0 0xc4 0x8 0x0 0xc9 0x8 0x0 0x0 0x8 0x0 0x0 0x8 0x0 0x0 0x8>;
		};

		DISP_OVL0@0x14007000 {
			compatible = "mediatek,DISP_OVL0";
			reg = <0x14007000 0x1000>;
			interrupts = <0x0 0xb8 0x8>;
		};

		DISP_OVL1@0x14008000 {
			compatible = "mediatek,DISP_OVL1";
			reg = <0x14008000 0x1000>;
			interrupts = <0x0 0xb9 0x8>;
		};

		DISP_RDMA0@0x14009000 {
			compatible = "mediatek,DISP_RDMA0";
			reg = <0x14009000 0x1000>;
			interrupts = <0x0 0xc7 0x8>;
		};

		DISP_RDMA1@0x1400A000 {
			compatible = "mediatek,DISP_RDMA1";
			reg = <0x1400a000 0x1000>;
			interrupts = <0x0 0xc8 0x8>;
		};

		DISP_WDMA0@0x1400B000 {
			compatible = "mediatek,DISP_WDMA0";
			reg = <0x1400b000 0x1000>;
			interrupts = <0x0 0xc6 0x8>;
		};

		DISP_COLOR@0x1400C000 {
			compatible = "mediatek,DISP_COLOR";
			reg = <0x1400c000 0x1000>;
			interrupts = <0x0 0xbd 0x8>;
		};

		DISP_CCORR@0x1400D000 {
			compatible = "mediatek,DISP_CCORR";
			reg = <0x1400d000 0x1000>;
			interrupts = <0x0 0xbe 0x8>;
		};

		DISP_AAL@0x1400E000 {
			compatible = "mediatek,DISP_AAL";
			reg = <0x1400e000 0x1000>;
			interrupts = <0x0 0xbf 0x8>;
		};

		DISP_GAMMA@0x1400F000 {
			compatible = "mediatek,DISP_GAMMA";
			reg = <0x1400f000 0x1000>;
			interrupts = <0x0 0xc0 0x8>;
		};

		DISP_DITHER@0x14010000 {
			compatible = "mediatek,DISP_DITHER";
			reg = <0x14010000 0x1000>;
			interrupts = <0x0 0xc1 0x8>;
		};

		DSI_UFOE@0x14011000 {
			compatible = "mediatek,DSI_UFOE";
			reg = <0x14011000 0x1000>;
		};

		DSI0@0x14012000 {
			compatible = "mediatek,DSI0";
			reg = <0x14012000 0x1000>;
			interrupts = <0x0 0xc3 0x8>;
		};

		DPI0@0x14013000 {
			compatible = "mediatek,DPI0";
			reg = <0x14013000 0x1000>;
			interrupts = <0x0 0xc4 0x8>;
		};

		DPI1@0x1401C000 {
			compatible = "mediatek,DPI1";
			reg = <0x1401c000 0x1000>;
			interrupts = <0x0 0xc9 0x8>;
		};

		DISP_PWM0@0x14014000 {
			compatible = "mediatek,DISP_PWM0";
			reg = <0x14014000 0x1000>;
		};

		MM_MUTEX@0x14015000 {
			compatible = "mediatek,MM_MUTEX";
			reg = <0x14015000 0x1000>;
			interrupts = <0x0 0xb1 0x8>;
		};

		SMI_LARB0@0x14016000 {
			compatible = "mediatek,SMI_LARB0";
			reg = <0x14016000 0x1000>;
			interrupts = <0x0 0xcd 0x8>;
		};

		SMI_COMMON@0x14017000 {
			compatible = "mediatek,SMI_COMMON";
			reg = <0x14017000 0x1000 0x14016000 0x1000 0x16010000 0x1000 0x15001000 0x1000 0x17001000 0x1000>;
		};

		DISP_WDMA1@0x14018000 {
			compatible = "mediatek,DISP_WDMA1";
			reg = <0x14018000 0x1000>;
		};

		UFOD_RDMA0@0x14019000 {
			compatible = "mediatek,UFOD_RDMA0";
			reg = <0x14019000 0x1000>;
		};

		UFOD_RDMA1@0x1401A000 {
			compatible = "mediatek,UFOD_RDMA1";
			reg = <0x1401a000 0x1000>;
		};

		SMI_LARB2@0x15001000 {
			compatible = "mediatek,SMI_LARB2";
			reg = <0x15001000 0x1000>;
			interrupts = <0x0 0xd9 0x8>;
		};

		ISPSYS@0x15000000 {
			compatible = "mediatek,ISPSYS";
			reg = <0x15004000 0x9000 0x15000000 0x10000 0x10217000 0x3000>;
			interrupts = <0x0 0xda 0x8 0x0 0xdb 0x8>;
		};

		IMGSYS@0x15000000 {
			compatible = "mediatek,IMGSYS";
			reg = <0x15000000 0x1000>;
		};

		KD_CAMERA_HW1@0x15008000 {
			compatible = "mediatek,CAMERA_HW";
			reg = <0x15008000 0x1000>;
		};

		KD_CAMERA_HW2@0x15008000 {
			compatible = "mediatek,CAMERA_HW2";
			reg = <0x15008000 0x1000>;
		};

		ISP_SYSR@0x15000000 {
			compatible = "mediatek,ISP_SYSR";
		};

		ISP_PIPEM@0x15000000 {
			compatible = "mediatek,ISP_PIPEM";
		};

		SENINF_TOP@0x15008000 {
			compatible = "mediatek,SENINF_TOP";
			reg = <0x15008000 0x1000>;
			interrupts = <0x0 0xda 0x8>;
		};

		CAM@0x15004000 {
			compatible = "mediatek,CAM";
			reg = <0x15004000 0x1000>;
			interrupts = <0x0 0xdb 0x8>;
		};

		VDEC_GCON@16000000 {
			compatible = "mediatek,VDEC_GCON";
			reg = <0x16000000 0x10000>;
		};

		SMI_LARB1@16010000 {
			compatible = "mediatek,SMI_LARB1";
			reg = <0x16010000 0x10000>;
			interrupts = <0x0 0xd5 0x8>;
		};

		VDEC@16020000 {
			compatible = "mediatek,VDEC";
			reg = <0x16020000 0x10000>;
			interrupts = <0x0 0xd4 0x8>;
		};

		MJC_CONFIG@0x12000000 {
			compatible = "mediatek,MJC_CONFIG";
			reg = <0x12000000 0x1000>;
		};

		MJC_TOP@0x12001000 {
			compatible = "mediatek,MJC_TOP";
			reg = <0x12001000 0x1000>;
			interrupts = <0x0 0xd7 0x8>;
		};

		VENC_GCON@17000000 {
			compatible = "mediatek,VENC_GCON";
			reg = <0x17000000 0x1000>;
		};

		SMI_LARB3@17001000 {
			compatible = "mediatek,SMI_LARB3";
			reg = <0x17001000 0x1000>;
			interrupts = <0x0 0xcf 0x8>;
		};

		VENC@17002000 {
			compatible = "mediatek,VENC";
			reg = <0x17002000 0x1000>;
			interrupts = <0x0 0xce 0x8>;
		};

		JPGENC@17003000 {
			compatible = "mediatek,JPGENC";
			reg = <0x17003000 0x1000>;
			interrupts = <0x0 0xd0 0x8>;
		};

		JPGDEC@17004000 {
			compatible = "mediatek,JPGDEC";
			reg = <0x17004000 0x1000>;
			interrupts = <0x0 0xd3 0x8>;
		};

		gpio@0x10001e00 {
			compatible = "mediatek,fpga_gpio";
			reg = <0x10001e00 0x100>;
		};

		AUXADC@11001000 {
			compatible = "mediatek,AUXADC";
			reg = <0x11001000 0x300>;
		};

		MDCLDMA@0x200F0000 {
			compatible = "mediatek,MDCLDMA";
			reg = <0x200f0000 0x3000 0x200e0000 0x3000 0x10209000 0x1000>;
			cell-index = <0x0>;
			interrupts = <0x0 0xe9 0x4 0x0 0x8b 0x8 0x0 0xe8 0x2>;
			cldma,major = <0xb8>;
			cldma,minor_base = <0x0>;
			cldma,capability = <0x2>;
		};

		HDMI@0x1401D000 {
			compatible = "mediatek,hdmitx";
			reg = <0x1401d000 0x1000 0x1100f000 0x10 0x10013000 0xbc>;
			interrupts = <0x0 0xca 0x8>;
		};

		hwmsensor@0 {
			compatible = "mediatek,hwmsensor";
		};

		gsensor@0 {
			compatible = "mediatek,gsensor";
		};

		als_ps@0 {
			compatible = "mediatek,als_ps";
		};

		m_acc_pl@0 {
			compatible = "mediatek,m_acc_pl";
		};

		m_alsps_pl@0 {
			compatible = "mediatek,m_alsps_pl";
		};

		sensorHub@0 {
			compatible = "mediatek,sensorHub";
		};

		shf@0 {
			compatible = "mediatek,shf";
		};

		m_batch_pl@0 {
			compatible = "mediatek,m_batch_pl";
		};

		gyroscope@0 {
			compatible = "mediatek,gyroscope";
		};

		m_gyro_pl@0 {
			compatible = "mediatek,m_gyro_pl";
		};

		barometer@0 {
			compatible = "mediatek,barometer";
		};

		m_baro_pl@0 {
			compatible = "mediatek,m_baro_pl";
		};

		msensor@0 {
			compatible = "mediatek,msensor";
		};

		m_mag_pl@0 {
			compatible = "mediatek,m_mag_pl";
		};

		orientation@0 {
			compatible = "mediatek,orientation";
		};

		pedometer@0 {
			compatible = "mediatek,pedometer";
		};

		m_pdr_pl@0 {
			compatible = "mediatek,m_pdr_pl";
		};

		step_counter@0 {
			compatible = "mediatek,step_counter";
		};

		m_step_c_pl@0 {
			compatible = "mediatek,m_step_c_pl";
		};

		in_pocket@0 {
			compatible = "mediatek,in_pocket";
		};

		m_inpk_pl@0 {
			compatible = "mediatek,m_inpk_pl";
		};

		shake@0 {
			compatible = "mediatek,shake";
		};

		m_shk_pl@0 {
			compatible = "mediatek,m_shk_pl";
		};

		face_down@0 {
			compatible = "mediatek,face_down";
		};

		m_fdn_pl@0 {
			compatible = "mediatek,m_fdn_pl";
		};

		activity@0 {
			compatible = "mediatek,activity";
		};

		m_act_pl@0 {
			compatible = "mediatek,m_act_pl";
		};

		heart_rate@0 {
			compatible = "mediatek,heart_rate";
		};

		m_hrm_pl@0 {
			compatible = "mediatek,m_hrm_pl";
		};

		tilt_detector@0 {
			compatible = "mediatek,tilt_detector";
		};

		m_tilt_pl@0 {
			compatible = "mediatek,m_tilt_pl";
		};

		wake_gesture@0 {
			compatible = "mediatek,wake_gesture";
		};

		m_wag_pl@0 {
			compatible = "mediatek,m_wag_pl";
		};

		glance_gesture@0 {
			compatible = "mediatek,glance_gesture";
		};

		m_glg_pl@0 {
			compatible = "mediatek,m_glg_pl";
		};

		pick_up@0 {
			compatible = "mediatek,pick_up";
		};

		m_pkup_pl@0 {
			compatible = "mediatek,m_pkup_pl";
		};

		MTKFB@0 {
			compatible = "mediatek,MTKFB";
		};

		CHIPID@08000000 {
			compatible = "mediatek,CHIPID";
			reg = <0x8000000 0x4 0x8000004 0x4 0x8000008 0x4 0x800000c 0x4>;
		};

		uibc@0 {
			compatible = "mediatek,uibc";
		};

		CQDMA@0x10212c00 {
			compatible = "mediatek,CQDMA";
			reg = <0x10212c00 0x1000>;
			interrupts = <0x0 0x8f 0x8>;
			nr_channel = <0x1>;
		};

		l2c_share@0x10200000 {
			compatible = "mediatek,l2c_share";
			reg = <0x10200000 0x4 0x10200200 0x4>;
			mediatek,l2c-share-cluster-num = <0x2>;
			mediatek,l2c-cluster-borrow = <0x1>;
			mediatek,l2c-cluster-return = <0x3>;
		};
	};

	psci {
		compatible = "arm,psci";
		method = "smc";
		cpu_suspend = <0x84000001>;
		cpu_off = <0x84000002>;
		cpu_on = <0x84000003>;
		affinity_info = <0x84000004>;
	};

	MOBICORE {
		compatible = "trustonic,mobicore";
		interrupts = <0x0 0x118 0x1>;
	};
};
